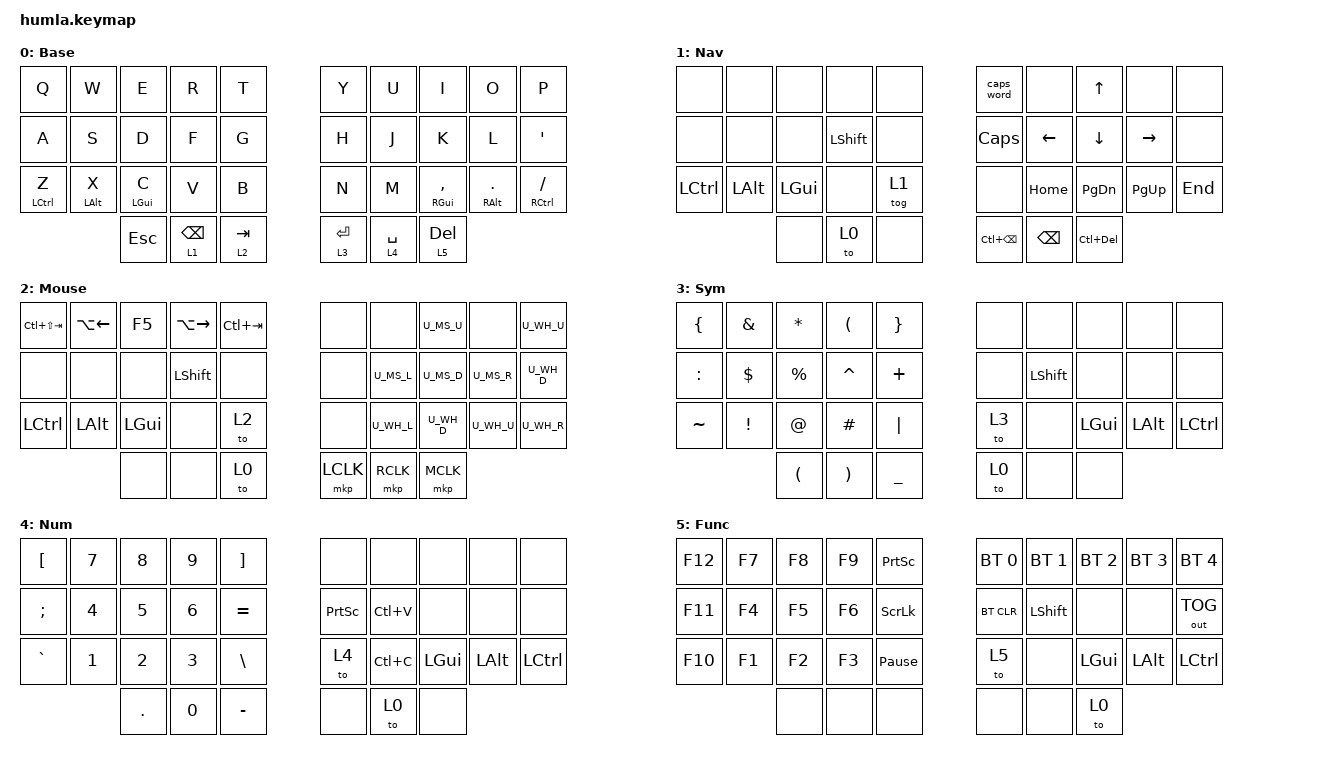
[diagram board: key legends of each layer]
/*
 * Copyright (c) 2020 The ZMK Contributors
 * SPDX-License-Identifier: MIT
 *
 * This is a QWERTY keymap for the Humla keyboard.
 * Last edited by Hans Lenze Kaper, 2024-04-21.
 */

#include <behaviors.dtsi>
#include "mouse.dtsi"
#include <dt-bindings/zmk/keys.h>
#include <dt-bindings/zmk/bt.h>
#include <dt-bindings/zmk/outputs.h>
#include <dt-bindings/zmk/mouse.h>

/*
 * 0  1  2  3  4       5  6  7  8  9
 * Q  W  E  R  T       Y  U  I  O  P
 * 
 * 10 11 12 13 14      15 16 17 18 19
 * A  S  D  F  G       H  J  K  L  ;
 * 
 * 20 21 22 23 24      25 26 27 28 29
 * Z  X  C  V  B       N  M  ,  .  /
 */

 / {
    combos {
        compatible = "zmk,combos";
        combo_esc {
            layers = <0>;
            timeout-ms = <25>;
            key-positions = <0 1>;
            bindings = <&kp ESC>;
        };
        combo_lshift {
            layers = <0>;
            timeout-ms = <25>;
            key-positions = <11 12>;
            bindings = <&sk LSHIFT>;
        };
        combo_rshift {
            layers = <0>;
            timeout-ms = <25>;
            key-positions = <17 18>;
            bindings = <&sk RSHIFT>;
        };
    };
};

/ {
    behaviors {
        td0: tap_dance_0 {
            compatible = "zmk,behavior-tap-dance";
            #binding-cells = <0>;
            tapping-term-ms = <100>;
            bindings = <&lt 4 SPACE>, <&kp SPACE>;
        };
        td1: tap_dance_1 {
            compatible = "zmk,behavior-tap-dance";
            #binding-cells = <0>;
            tapping-term-ms = <100>;
            bindings = <&lt 1 BSPC>, <&kp BSPC>;
        };
    };
};

&mt {
    tapping-term-ms = <280>;
    flavor = "tap-preferred";
};

&lt {
    tapping-term-ms = <230>;
    flavor = "balanced";
};

/ {
    keymap {
        compatible = "zmk,keymap";

        default_layer {
            label = "Base";
            bindings = <
                &kp Q          &kp W        &kp E       &kp R     &kp T           &kp Y       &kp U     &kp I           &kp O         &kp P
                &kp A          &kp S        &kp D       &kp F     &kp G           &kp H       &kp J     &kp K           &kp L         &kp SQT
                &mt LCTL Z     &mt LALT X   &mt LGUI C  &kp V     &kp B           &kp N       &kp M     &mt RGUI COMMA  &mt RALT DOT  &mt RCTL SLASH
                                            &kp ESC     &lt 1 BSPC      &lt 2 TAB       &lt 3 ENTER &lt 4 SPACE      &lt 5 DEL
            >;
        };

        nav_layer {
            label = "Nav";
            bindings = <
                &none       &none       &none       &none       &none       &caps_word       &none       &kp UP       &none       &none 
                &none       &none       &none       &kp LSHIFT  &none       &kp CAPS    &kp LEFT    &kp DOWN     &kp RIGHT   &none
                &kp LCTL    &kp LALT    &kp LGUI    &none       &tog 1      &none       &kp HOME    &kp PG_DN    &kp PG_UP   &kp END
                                        &none       &to 0       &none       &kp LC(BSPC)       &kp BSPC       &kp LC(DEL)
            >;
        };

        mouse_layer {
            label = "Mouse";
            bindings = <
                &kp LC(LS(TAB)) &kp LA(LEFT)  &kp F5      &kp LA(RIGHT)   &kp LC(TAB)  &none       &none      U_MS_U     &none    U_WH_U 
                &none           &none         &none       &kp LSHIFT      &none        &none       U_MS_L     U_MS_D     U_MS_R   U_WH_D
                &kp LCTL        &kp LALT      &kp LGUI    &none           &to 2        &none       U_WH_L     U_WH_D     U_WH_U   U_WH_R
                                              &none       &none           &to 0        &mkp LCLK   &mkp RCLK  &mkp MCLK
            >;
        };
        
        sym_layer {
            label = "Sym";
            bindings = <
                &kp LBRC    &kp AMPS   &kp STAR   &kp LPAR   &kp RBRC         &none    &none       &none    &none    &none
                &kp COLON   &kp DLLR   &kp PRCNT  &kp CARET  &kp PLUS         &none    &kp LSHIFT  &none    &none    &none
                &kp TILDE   &kp EXCL   &kp AT     &kp HASH   &kp PIPE         &to 3    &none       &kp LGUI &kp LALT &kp LCTL
                                       &kp LPAR   &kp RPAR   &kp UNDER        &to 0    &none       &none
            >;
        };

        num_layer {
            label = "Num";
            bindings = <
                &kp LBKT   &kp N7   &kp N8   &kp N9   &kp RBKT         &none     &none       &none     &none     &none
                &kp SEMI   &kp N4   &kp N5   &kp N6   &kp EQUAL        &kp PSCRN &kp LC(V)  &none     &none     &none
                &kp GRAVE  &kp N1   &kp N2   &kp N3   &kp BACKSLASH    &to 4     &kp LC(C)       &kp LGUI  &kp LALT  &kp LCTL
                                    &kp DOT  &kp N0   &kp MINUS        &none     &to 0       &none
            >;
        };

        func_layer {
            label = "Func";
            bindings = <
                &kp F12   &kp F7  &kp F8    &kp F9     &kp PSCRN       &bt BT_SEL 0  &bt BT_SEL 1  &bt BT_SEL 2   &bt BT_SEL 3   &bt BT_SEL 4
                &kp F11   &kp F4  &kp F5    &kp F6     &kp SLCK        &bt BT_CLR    &kp LSHIFT    &none          &none          &out OUT_TOG
                &kp F10   &kp F1  &kp F2    &kp F3     &kp PAUSE_BREAK &to 5         &none         &kp LGUI       &kp LALT       &kp LCTL
                                  &none     &none      &none           &none         &none         &to 0
            >;
        };

    };
};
